# PIC32CK1012SG00100 register map
Vendor: Microchip Technology; Series: PIC32CKSG00; File version: 0
CPU: CM33 r0p0, little endian, MPU, FPU, DSP, 3 interrupt priority bits, 159 interrupts, 18 SAU regions
Registers are 32-bit, read-write, reset 0x0 unless marked. A register's access mark holds for its fields unless they carry their own. Offsets are from the block's base; [hi:lo] are bit positions; {n}, {i} and the like mark numbered series; 'fields as' and 'values as' point back to an identical list.

## DSU — Device Service Unit
Base 0x44000000
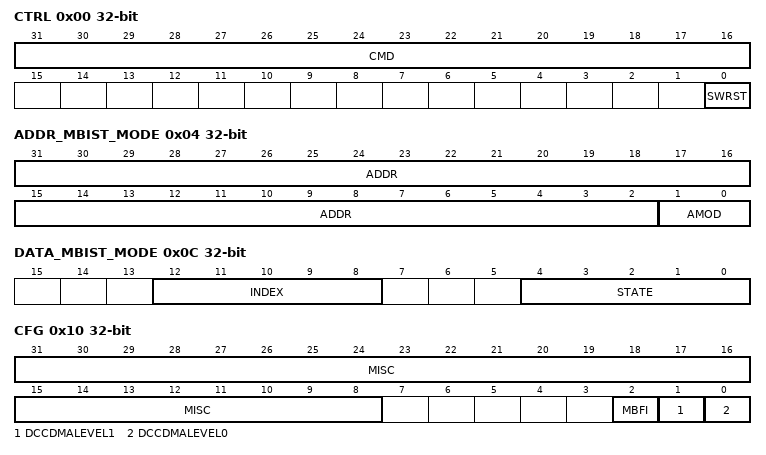
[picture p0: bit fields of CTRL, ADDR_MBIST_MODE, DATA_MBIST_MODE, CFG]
0x00 CTRL wo — Control
  [31:16] CMD — Command Register
    0=NOOP (No operation); 0xA500=CRC32 (32-bit Cyclic Redundancy Code); 0xA501=MBIST (Global Memory built-in self-test); 0xA502=MSET (Memory Set)
  [0] SWRST — Software Reset
0x04 ADDR — Address
  [31:2] ADDR
0x04 ADDR_MBIST_MODE (alternate view of ADDR) — Address
  [31:2] ADDR — Address
  [1:0] AMOD — Access Mode
    0=EXIT_ON_ERROR (STATUSA.FAIL rises upon first error and algorithm stops (STATUSA.DONE rises).); 1=PAUSE_ON_ERROR (STATUSA.FAIL rises when an error is detected and algorith stops until STATUSA.FAIL is cleared. Once cleared, the algorithm is resumed going to next test step.)
0x08 LENGTH
  [31:2] LENGTH
0x0C DATA
0x0C DATA_MBIST_MODE (alternate view of DATA) — Data
  [12:8] INDEX — MBIST bit Index
  [4:0] STATE — MBIST state
    9=SET1 (SET1 Phase: read '0' write '1'); 10=SET2 (SET2 Phase: read '1' write '0'); 11=SET2B (SET2B Phase: read '0' write '1'); 12=CLEAR1 (CLEAR1 Phase: read '1' write '0'); 13=CLEAR2 (CLEAR2 Phase: read '0' write '1'); 14=CLEAR2B (CLEAR2B Phase: read '1' write '0'); 15=READ (READ Phase: check memory is cleared)
0x10 CFG — Configuration
  [31:8] MISC — Device Specific Configuration Register
  [2] MBFI — Enables the Memory Bist Fault Injection
  [1] DCCDMALEVEL1 — DMA Trigger 1 Level
    0=EMPTY (Trigger x rises when DCC is read and falls when it is written); 1=FULL (Trigger x rises when DCC is written and falls when it is read)
  [0] DCCDMALEVEL0 — DMA Trigger 0 Level
    values as DCCDMALEVEL1
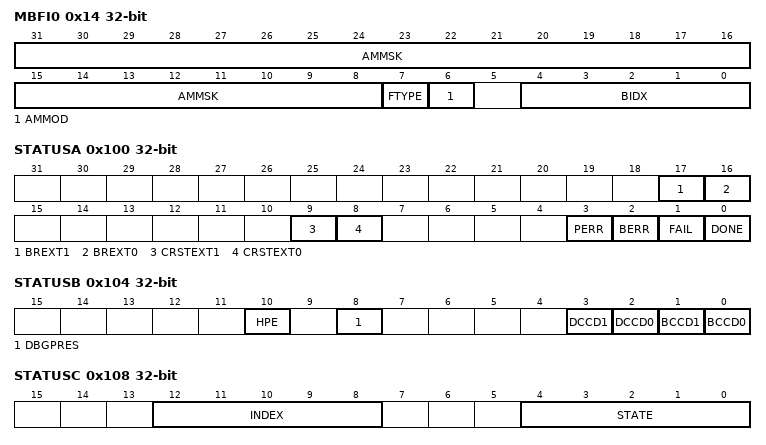
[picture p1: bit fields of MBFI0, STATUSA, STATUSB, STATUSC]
0x14 MBFI0 — Memory Bist Fault Injection 0
  [31:8] AMMSK — Address matching Mask (Word address)
  [7] FTYPE — Fault type
    0=STUCKAT0; 1=STUCKAT1
  [6] AMMOD — Address matching mode
    0=ADDR (Address match, fault injected when the masked master address matches with the masked bcc1.addr); 1=ALWAYS (Always matches, fault injected every AHB access)
  [4:0] BIDX — Bit Index of injected fault
0x18 MBFI1 — Memory Bist Fault Injection 1
  [31:2] ADDR — Word Address
0x100 STATUSA
  [17] BREXT1 — BootRom 1 Phase Extension
  [16] BREXT0 — BootRom 0 Phase Extension
  [9] CRSTEXT1 — CPU 1 Reset Phase Extension
  [8] CRSTEXT0 — CPU 0 Reset Phase Extension
  [3] PERR — Protection Error
  [2] BERR — Bus Error
  [1] FAIL — Failure
  [0] DONE
0x104 STATUSB ro
  [10] HPE — Hot-Plugging Enable
  [8] DBGPRES — Debugger Present
  [3] DCCD1 — Debug Communication Channel 1 Dirty
  [2] DCCD0 — Debug Communication Channel 0 Dirty
  [1] BCCD1 — Boot ROM Communication Channel 1 Dirty
  [0] BCCD0 — Boot ROM Communication Channel 0 Dirty
0x108 STATUSC ro
  [12:8] INDEX — MBIST, MSA, PMSA bit Index
  [4:0] STATE — Core State
    0=IDLE (State Machine Ready); 1=CRC32 (CRC32 Operation Ongoing); 4=MSET (Memory Set); 8=MBIST_FILL (MBIST fill memory with zeroes); 9=MBIST_SET1 (SET1 Phase: read '0' write '1'); 10=MBIST_SET2 (SET2 Phase: read '1' write '0'); 11=MBIST_SET2B (SET2B Phase: read '0' write '1'); 12=MBIST_CLEAR1 (CLEAR1 Phase: read '1' write '0'); 13=MBIST_CLEAR2 (CLEAR2 Phase: read '0' write '1'); 14=MBIST_CLEAR2B (CLEAR2B Phase: read '1' write '0'); 15=MBIST_READ (READ Phase: check memory is cleared)
{0x110+4i} BCC[{i}] (i=0..1) — Boot ROM Communication Channel x
  [31:0] DATA
{0x118+4i} DCC[{i}] (i=0..1) — Debug Communication Channel x
  [31:0] DATA
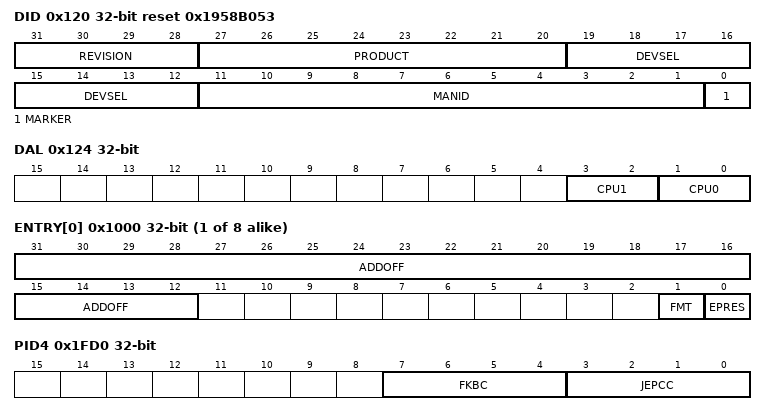
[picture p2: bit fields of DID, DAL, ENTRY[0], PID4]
0x120 DID ro reset 0x1958B053 — Device Identification
  [31:28] REVISION
  [27:20] PRODUCT
  [19:12] DEVSEL — Device Select
  [11:1] MANID — Manufacturer ID
  [0] MARKER — Marker Bit
0x124 DAL ro — Debugger Access Level
  [3:2] CPU1 — Per CPU Debugger Access Level
    0=SECURED (Debugger targeting CPU0 domain can only access the DSU external address space otherwise debugger access is disabled); 1=NS_DEBUG (Debugger can access only non-secure regions); 2=FULL_DEBUG (Debugger can access secure and non-secure regions); 3=UNIMPLEMENTED (No CPU in this slot)
  [1:0] CPU0 — Per CPU Debugger Access Level
    values as CPU1
{0x1000+4i} ENTRY[{i}] (i=0..7) ro — Coresight ROM Table Entry x
  [31:12] ADDOFF — Address Offset
  [1] FMT — Format
  [0] EPRES — Entry Present
0x1FCC MEMTYPE ro — Coresight ROM Table Memory Type
  [0] SMEMP — System Memory Present
0x1FD0 PID4 ro — Coresight ROM Table Peripheral Identification 4
  [7:4] FKBC — 4KB count
  [3:0] JEPCC — JEP-106 Continuation Code
{0x1FC0+4i} PID{i} ro (i=5..7) — Coresight ROM Table Peripheral Identification {i}
0x1FE0 PID0 ro reset 0xD0 — Coresight ROM Table Peripheral Identification 0
  [7:0] PARTNBL — Part Number Low
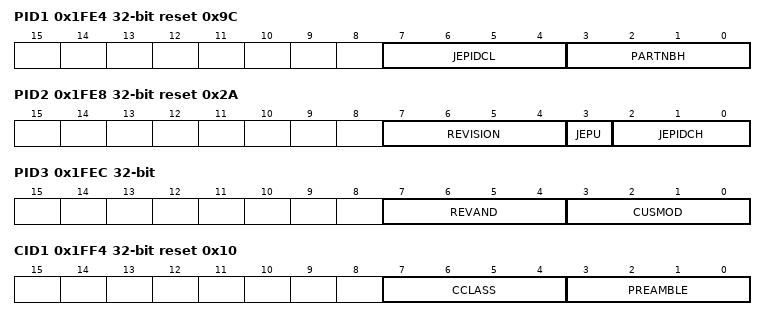
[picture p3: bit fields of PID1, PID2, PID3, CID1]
0x1FE4 PID1 ro reset 0x9C — Coresight ROM Table Peripheral Identification 1
  [7:4] JEPIDCL — Low part of the JEP-106 Identity Code
  [3:0] PARTNBH — Part Number High
0x1FE8 PID2 ro reset 0x2A — Coresight ROM Table Peripheral Identification 2
  [7:4] REVISION — Revision Number
  [3] JEPU — JEP-106 Identity Code is used
  [2:0] JEPIDCH — JEP-106 Identity Code High
0x1FEC PID3 ro — Coresight ROM Table Peripheral Identification 3
  [7:4] REVAND — Revision Number
  [3:0] CUSMOD — ARM CUSMOD
0x1FF0 CID0 ro reset 0xD — Coresight ROM Table Component Identification 0
  [7:0] PREAMBLEB0 — Preamble Byte 0
0x1FF4 CID1 ro reset 0x10 — Coresight ROM Table Component Identification 1
  [7:4] CCLASS — Component Class
  [3:0] PREAMBLE
0x1FF8 CID2 ro reset 0x5 — Coresight ROM Table Component Identification 2
  [7:0] PREAMBLEB2 — Preamble Byte 2
0x1FFC CID3 ro reset 0xB1 — Coresight ROM Table Component Identification 3
  [7:0] PREAMBLEB3 — Preamble Byte 3

## Notices in the file
Copyright (c) 2026 Microchip Technology Inc.
SPDX-License-Identifier: Apache-2.0
Licensed under the Apache License, Version 2.0 (the "License");
you may not use this file except in compliance with the License.
You may obtain a copy of the License at
http://www.apache.org/licenses/LICENSE-2.0
Unless required by applicable law or agreed to in writing, software
distributed under the License is distributed on an "AS IS" BASIS,
WITHOUT WARRANTIES OR CONDITIONS OF ANY KIND, either express or implied.
See the License for the specific language governing permissions and
limitations under the License.
